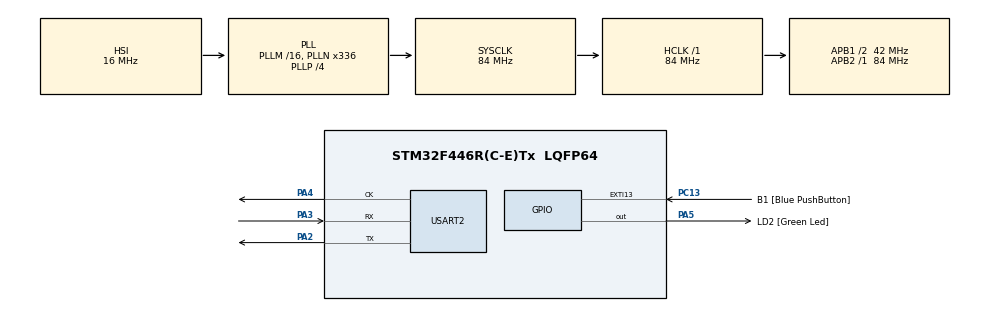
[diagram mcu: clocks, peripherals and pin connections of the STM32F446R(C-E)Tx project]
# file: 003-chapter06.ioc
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Mcu.Family=STM32F4
Mcu.Name=STM32F446R(C-E)Tx
Mcu.Package=LQFP64
NVIC.PriorityGroup=NVIC_PRIORITYGROUP_0
PA13.GPIO_Label=TMS
PA13.Mode=Serial_Wire
PA13.Signal=SYS_JTMS-SWDIO
PA14.GPIO_Label=TCK
PA14.Mode=Serial_Wire
PA14.Signal=SYS_JTCK-SWCLK
PA2.GPIO_Speed=GPIO_SPEED_FREQ_LOW
PA2.Mode=Synchronous
PA2.Signal=USART2_TX
PA3.GPIO_Speed=GPIO_SPEED_FREQ_LOW
PA3.Mode=Synchronous
PA3.Signal=USART2_RX
PA4.GPIO_Speed=GPIO_SPEED_FREQ_LOW
PA4.Mode=Synchronous
PA4.Signal=USART2_CK
PA5.GPIO_Label=LD2 [Green Led]
PA5.Signal=GPIO_Output
PB3.GPIO_Label=SWO
PB3.Signal=SYS_JTDO-SWO
PC13.GPIO_Label=B1 [Blue PushButton]
PC13.GPIO_ModeDefaultEXTI=GPIO_MODE_IT_FALLING
PC13.Signal=GPXTI13
PC14-OSC32_IN.Mode=LSE-External-Oscillator
PC14-OSC32_IN.Signal=RCC_OSC32_IN
PC15-OSC32_OUT.Mode=LSE-External-Oscillator
PC15-OSC32_OUT.Signal=RCC_OSC32_OUT
PH0-OSC_IN.Mode=HSE-External-Oscillator
PH0-OSC_IN.Signal=RCC_OSC_IN
PH1-OSC_OUT.Mode=HSE-External-Oscillator
PH1-OSC_OUT.Signal=RCC_OSC_OUT
ProjectManager.HeapSize=0x200
ProjectManager.StackSize=0x400
ProjectManager.TargetToolchain=STM32CubeIDE
RCC.48MHZClocksFreq_Value=84000000
RCC.AHBFreq_Value=84000000
RCC.APB1CLKDivider=RCC_HCLK_DIV2
RCC.APB1Freq_Value=42000000
RCC.APB1TimFreq_Value=84000000
RCC.APB2Freq_Value=84000000
RCC.APB2TimFreq_Value=84000000
RCC.CortexFreq_Value=84000000
RCC.FLatency-AdvancedSettings=FLASH_LATENCY_2
RCC.HCLKFreq_Value=84000000
RCC.HSE_VALUE=8000000
RCC.HSI_VALUE=16000000
RCC.PLLN=336
RCC.PLLP=RCC_PLLP_DIV4
RCC.SYSCLKFreq_VALUE=84000000
RCC.SYSCLKSource=RCC_SYSCLKSOURCE_PLLCLK
RCC.USBFreq_Value=168000000
RCC.VCOOutputFreq_Value=336000000
USART2.VirtualMode=VM_SYNC
board=NUCLEO-F446RE

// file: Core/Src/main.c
/* USER CODE BEGIN Header */
/**
  ******************************************************************************
  * @file           : main.c
  * @brief          : Main program body
  ******************************************************************************
  * @attention
  *
  * Copyright (c) 2023 STMicroelectronics.
  * All rights reserved.
  *
  * This software is licensed under terms that can be found in the LICENSE file
  * in the root directory of this software component.
  * If no LICENSE file comes with this software, it is provided AS-IS.
  *
  ******************************************************************************
  */
/* USER CODE END Header */
#include "main.h"

USART_HandleTypeDef husart2;

void SystemClock_Config(void);
static void MX_GPIO_Init(void);
static void MX_USART2_Init(void);

int main(void)
{
  /* USER CODE BEGIN 1 */
	volatile uint32_t *GPIOA_MODER = 0x0;
	volatile uint32_t *GPIOA_ODR = 0x0;

  /* USER CODE END 1 */

  /* MCU Configuration--------------------------------------------------------*/

  /* Reset of all peripherals, Initializes the Flash interface and the Systick. */
  HAL_Init();

  /* USER CODE BEGIN Init */
  GPIOA_MODER = (uint32_t *)0x40020000U; // address of the GPIOA->MODER register
  GPIOA_ODR = (uint32_t *)(0x40020000U + 0x14); // address of the GPIOA->ODR register

  /* USER CODE END Init */

  /* Configure the system clock */
  SystemClock_Config();

  /* Initialize all configured peripherals */
  MX_GPIO_Init();
  MX_USART2_Init();
  /* USER CODE BEGIN 2 */
  // This ensures that the peripheral is enabled and connected to the AHB1 bus
  __HAL_RCC_GPIOA_CLK_ENABLE();

  // Sets MODER[11:10] = 0x1
  *GPIOA_MODER = *GPIOA_MODER | 0x400;
  // Sets ODR[5] = 0x1, that is pulls PA5 high
  *GPIOA_ODR = *GPIOA_ODR | 0x20;

  /* USER CODE END 2 */

  /* Infinite loop */
  while (1)
  {

  }
}

void SystemClock_Config(void)
{
  RCC_OscInitTypeDef RCC_OscInitStruct = {0};
  RCC_ClkInitTypeDef RCC_ClkInitStruct = {0};

  /** Configure the main internal regulator output voltage
  */
  __HAL_RCC_PWR_CLK_ENABLE();
  __HAL_PWR_VOLTAGESCALING_CONFIG(PWR_REGULATOR_VOLTAGE_SCALE3);

  /** Initializes the RCC Oscillators according to the specified parameters
  * in the RCC_OscInitTypeDef structure.
  */
  RCC_OscInitStruct.OscillatorType = RCC_OSCILLATORTYPE_HSI;
  RCC_OscInitStruct.HSIState = RCC_HSI_ON;
  RCC_OscInitStruct.HSICalibrationValue = RCC_HSICALIBRATION_DEFAULT;
  RCC_OscInitStruct.PLL.PLLState = RCC_PLL_ON;
  RCC_OscInitStruct.PLL.PLLSource = RCC_PLLSOURCE_HSI;
  RCC_OscInitStruct.PLL.PLLM = 16;
  RCC_OscInitStruct.PLL.PLLN = 336;
  RCC_OscInitStruct.PLL.PLLP = RCC_PLLP_DIV4;
  RCC_OscInitStruct.PLL.PLLQ = 2;
  RCC_OscInitStruct.PLL.PLLR = 2;
  if (HAL_RCC_OscConfig(&RCC_OscInitStruct) != HAL_OK)
  {
    Error_Handler();
  }

  /** Initializes the CPU, AHB and APB buses clocks
  */
  RCC_ClkInitStruct.ClockType = RCC_CLOCKTYPE_HCLK|RCC_CLOCKTYPE_SYSCLK
                              |RCC_CLOCKTYPE_PCLK1|RCC_CLOCKTYPE_PCLK2;
  RCC_ClkInitStruct.SYSCLKSource = RCC_SYSCLKSOURCE_PLLCLK;
  RCC_ClkInitStruct.AHBCLKDivider = RCC_SYSCLK_DIV1;
  RCC_ClkInitStruct.APB1CLKDivider = RCC_HCLK_DIV2;
  RCC_ClkInitStruct.APB2CLKDivider = RCC_HCLK_DIV1;

  if (HAL_RCC_ClockConfig(&RCC_ClkInitStruct, FLASH_LATENCY_2) != HAL_OK)
  {
    Error_Handler();
  }
}

static void MX_USART2_Init(void)
{

  husart2.Instance = USART2;
  husart2.Init.BaudRate = 115200;
  husart2.Init.WordLength = USART_WORDLENGTH_8B;
  husart2.Init.StopBits = USART_STOPBITS_1;
  husart2.Init.Parity = USART_PARITY_NONE;
  husart2.Init.Mode = USART_MODE_TX_RX;
  husart2.Init.CLKPolarity = USART_POLARITY_LOW;
  husart2.Init.CLKPhase = USART_PHASE_1EDGE;
  husart2.Init.CLKLastBit = USART_LASTBIT_DISABLE;
  if (HAL_USART_Init(&husart2) != HAL_OK)
  {
    Error_Handler();
  }

}

static void MX_GPIO_Init(void)
{
  GPIO_InitTypeDef GPIO_InitStruct = {0};

  /* GPIO Ports Clock Enable */
  __HAL_RCC_GPIOC_CLK_ENABLE();
  __HAL_RCC_GPIOH_CLK_ENABLE();
  __HAL_RCC_GPIOA_CLK_ENABLE();
  __HAL_RCC_GPIOB_CLK_ENABLE();

  /*Configure GPIO pin Output Level */
  HAL_GPIO_WritePin(LD2_GPIO_Port, LD2_Pin, GPIO_PIN_RESET);

  /*Configure GPIO pin : B1_Pin */
  GPIO_InitStruct.Pin = B1_Pin;
  GPIO_InitStruct.Mode = GPIO_MODE_IT_FALLING;
  GPIO_InitStruct.Pull = GPIO_NOPULL;
  HAL_GPIO_Init(B1_GPIO_Port, &GPIO_InitStruct);

  /*Configure GPIO pin : LD2_Pin */
  GPIO_InitStruct.Pin = LD2_Pin;
  GPIO_InitStruct.Mode = GPIO_MODE_OUTPUT_PP;
  GPIO_InitStruct.Pull = GPIO_NOPULL;
  GPIO_InitStruct.Speed = GPIO_SPEED_FREQ_LOW;
  HAL_GPIO_Init(LD2_GPIO_Port, &GPIO_InitStruct);

}

void Error_Handler(void)
{
  __disable_irq();
  while (1)
  {
  }
}
